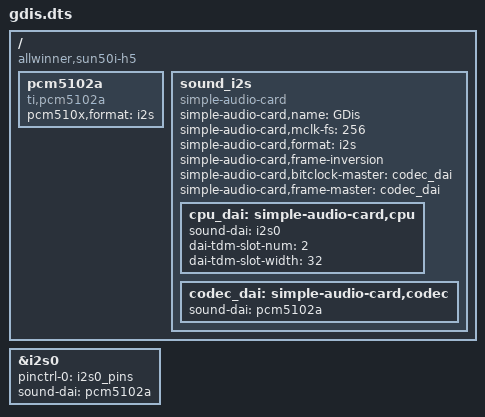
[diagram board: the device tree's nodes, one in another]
/dts-v1/;
/plugin/;

/ {
	compatible = "allwinner,sun50i-h5";

	fragment@0 {
		target-path = "/";
		__overlay__ {
			pcm5102a: pcm5102a {
			#sound-dai-cells = <0>;
			compatible = "ti,pcm5102a";
			pcm510x,format = "i2s";
			};
		};
	};

	fragment@1 {
		target = <&i2s0>;
		__overlay__ {
			status = "okay";
			pinctrl-0 = <&i2s0_pins>;
			sound-dai = <&pcm5102a>;
			pinctrl-names = "default";
		};
	};

	fragment@2 {
		target-path = "/";
		__overlay__ {
			sound_i2s {
				compatible = "simple-audio-card";
				simple-audio-card,name = "GDis";
				simple-audio-card,mclk-fs = <256>;
				simple-audio-card,format = "i2s";
                simple-audio-card,frame-inversion;
				simple-audio-card,bitclock-master = <&codec_dai>;
				simple-audio-card,frame-master = <&codec_dai>;
		        status = "okay";

				cpu_dai: simple-audio-card,cpu {
				sound-dai = <&i2s0>;
				dai-tdm-slot-num = <2>;
				dai-tdm-slot-width = <32>;
				};

				codec_dai: simple-audio-card,codec {
				sound-dai = <&pcm5102a>;
				};
			};
		};
	};
};
